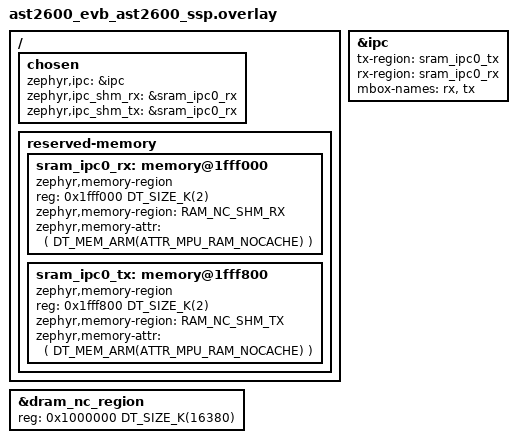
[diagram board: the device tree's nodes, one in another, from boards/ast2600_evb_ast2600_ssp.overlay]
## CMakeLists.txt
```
# SPDX-License-Identifier: Apache-2.0

cmake_minimum_required(VERSION 3.20.0)

find_package(Zephyr REQUIRED HINTS $ENV{ZEPHYR_BASE})
project(ipm_aspeed)

target_include_directories(app PRIVATE ${ZEPHYR_BASE}/drivers)
target_sources(app PRIVATE src/main.c)
```

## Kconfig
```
# Private config options for shared memory sample app

# Copyright (c) 2020 Linaro Limited
# SPDX-License-Identifier: Apache-2.0

# Workaround for not being able to have commas in macro arguments
DT_CHOSEN_Z_IPC := zephyr,ipc_legacy
DT_CHOSEN_Z_IPC_RX_SHM := zephyr,ipc_shm_rx
DT_CHOSEN_Z_IPC_TX_SHM := zephyr,ipc_shm_tx

config OPENAMP_IPC_DEV_NAME
	string
	default "$(dt_chosen_label,$(DT_CHOSEN_Z_IPC))"
	help
	  This option specifies the device name for the IPC device to be used

config IPC_SHM_RX_SIZE
	hex
	default "$(dt_chosen_reg_size_hex,$(DT_CHOSEN_Z_IPC_RX_SHM))"
	help
	  This option specifies size of the memory region to be used
	  for the IPC shared memory

config IPC_SHM_TX_SIZE
	hex
	default "$(dt_chosen_reg_size_hex,$(DT_CHOSEN_Z_IPC_TX_SHM))"
	help
	  This option specifies size of the memory region to be used
	  for the IPC shared memory

source "Kconfig.zephyr"
```

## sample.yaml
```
sample:
  description: the sample reads the received data from the Messaging Unit
    using the IPM and transmits it back unchanged
  name: Aspeed IPM sample
tests:
  sample.ipm.ipm_aspeed:
    build_only: true
    filter: CONFIG_SOC_FAMILY_ASPEED
    platform_allow:
      - ast2700_evb/ast2700/ssp
      - ast2700_evb/ast2700/tsp
      - ast2600_evb/ast2600/ssp
    integration_platforms:
      - ast2700_evb/ast2700/ssp
      - ast2700_evb/ast2700/tsp
      - ast2600_evb/ast2600/ssp
    tags: samples ipm
```

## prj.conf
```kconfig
CONFIG_STDOUT_CONSOLE=n
CONFIG_LOG=y
CONFIG_PRINTK=y
CONFIG_IPM=y
CONFIG_SHELL=y
```

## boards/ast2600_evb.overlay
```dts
/ {
	chosen {
		zephyr,ipc = &ipc;
	};
};

&ipc {
	status = "okay";
	shm_size = <DT_SIZE_K(4)>;
};
```

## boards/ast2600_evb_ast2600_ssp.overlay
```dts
/* SPDX-License-Identifier: Apache-2.0 */

#include <zephyr/dt-bindings/memory-attr/memory-attr-arm.h>

/ {
	chosen {
		zephyr,ipc = &ipc;
		zephyr,ipc_shm_rx = &sram_ipc0_rx;
		zephyr,ipc_shm_tx = &sram_ipc0_rx;
	};

	reserved-memory {
		#address-cells = <1>;
		#size-cells = <1>;
		ranges;
		/* SRAM allocated to shared memory */
		sram_ipc0_rx: memory@1fff000 {
			compatible = "zephyr,memory-region", "mmio-dram";
			reg = <0x1fff000 DT_SIZE_K(2)>;
			zephyr,memory-region = "RAM_NC_SHM_RX";
			zephyr,memory-attr = <( DT_MEM_ARM(ATTR_MPU_RAM_NOCACHE) )>;
		};

		/* SRAM allocated to shared memory */
		sram_ipc0_tx: memory@1fff800 {
			compatible = "zephyr,memory-region", "mmio-dram";
			device_type = "memory";
			reg = <0x1fff800 DT_SIZE_K(2)>;
			zephyr,memory-region = "RAM_NC_SHM_TX";
			zephyr,memory-attr = <( DT_MEM_ARM(ATTR_MPU_RAM_NOCACHE) )>;
		};
	};
};

&dram_nc_region {
	reg = <0x1000000 DT_SIZE_K(16380)>;
};

&ipc {
	tx-region = <&sram_ipc0_tx>;
	rx-region = <&sram_ipc0_rx>;
	mbox-names = "rx", "tx";
	status = "okay";
};
```

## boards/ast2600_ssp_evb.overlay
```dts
/ {
	chosen {
		zephyr,ipc = &ipc;
		zephyr,ipc_shm_rx = &sram_ipc0_rx;
		zephyr,ipc_shm_tx = &sram_ipc0_rx;
	};

	reserved-memory {
		#address-cells = <1>;
		#size-cells = <1>;
		ranges;
		/* SRAM allocated to shared memory */
		sram_ipc0_rx: memory@1fff000 {
			compatible = "zephyr,memory-region", "mmio-dram";
			reg = <0x1fff000 DT_SIZE_K(2)>;
			zephyr,memory-region = "RAM_NC_SHM_RX";
			zephyr,memory-region-mpu = "RAM";
		};

		/* SRAM allocated to shared memory */
		sram_ipc0_tx: memory@1fff800 {
			compatible = "zephyr,memory-region", "mmio-dram";
			device_type = "memory";
			reg = <0x1fff800 DT_SIZE_K(2)>;
			zephyr,memory-region = "RAM_NC_SHM_TX";
			zephyr,memory-region-mpu = "RAM";
		};
	};
};

&sdram1 {
	reg = <0x1000000 DT_SIZE_K(16380)>;
};

&ipc {
	tx-region = <&sram_ipc0_tx>;
	rx-region = <&sram_ipc0_rx>;
	mbox-names = "rx", "tx";
	status = "okay";
};
```

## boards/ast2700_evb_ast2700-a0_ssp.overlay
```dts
/* SPDX-License-Identifier: Apache-2.0 */

#include <zephyr/dt-bindings/memory-attr/memory-attr-arm.h>

/ {
	chosen {
		zephyr,ipc = &ipc_legacy;
		zephyr,ipc_shm_rx = &sram_ipc0_rx;
		zephyr,ipc_shm_tx = &sram_ipc0_tx;
	};

	reserved-memory {
		#address-cells = <1>;
		#size-cells = <1>;
		ranges;
		/* SRAM allocated to shared memory */
		sram_ipc0_rx: memory@ff000 {
			compatible = "zephyr,memory-region", "mmio-dram";
			reg = <0xff000 DT_SIZE_K(2)>;
			zephyr,memory-region = "RAM_NC_SHM_RX";
			zephyr,memory-attr = <( DT_MEM_ARM(ATTR_MPU_RAM_NOCACHE) )>;
		};

		/* SRAM allocated to shared memory */
		sram_ipc0_tx: memory@ff800 {
			compatible = "zephyr,memory-region", "mmio-dram";
			device_type = "memory";
			reg = <0xff800 DT_SIZE_K(2)>;
			zephyr,memory-region = "RAM_NC_SHM_TX";
			zephyr,memory-attr = <( DT_MEM_ARM(ATTR_MPU_RAM_NOCACHE) )>;
		};
	};
};

&dram_nc_region {
	reg = <0xc0000 DT_SIZE_K(252)>;
};

&ipc_legacy {
	tx-region = <&sram_ipc0_tx>;
	rx-region = <&sram_ipc0_rx>;
	mbox-names = "rx", "tx";
	status = "okay";
};
```

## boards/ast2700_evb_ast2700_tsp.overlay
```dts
/* SPDX-License-Identifier: Apache-2.0 */

#include <zephyr/dt-bindings/memory-attr/memory-attr-arm.h>

/ {
	chosen {
		zephyr,ipc = &ipc;
		zephyr,ipc_shm_rx = &sram_ipc0_rx;
		zephyr,ipc_shm_tx = &sram_ipc0_tx;
	};

	reserved-memory {
		#address-cells = <1>;
		#size-cells = <1>;
		ranges;
		/* SRAM allocated to shared memory */
		sram_ipc0_rx: memory@ff000 {
			compatible = "zephyr,memory-region", "mmio-dram";
			reg = <0xff000 DT_SIZE_K(2)>;
			zephyr,memory-region = "RAM_NC_SHM_RX";
			zephyr,memory-attr = <( DT_MEM_ARM(ATTR_MPU_RAM_NOCACHE) )>;
		};

		/* SRAM allocated to shared memory */
		sram_ipc0_tx: memory@ff800 {
			compatible = "zephyr,memory-region", "mmio-dram";
			device_type = "memory";
			reg = <0xff800 DT_SIZE_K(2)>;
			zephyr,memory-region = "RAM_NC_SHM_TX";
			zephyr,memory-attr = <( DT_MEM_ARM(ATTR_MPU_RAM_NOCACHE) )>;
		};
	};
};

&dram_nc_region {
	reg = <0xc0000 DT_SIZE_K(252)>;
};

&ipc {
	tx-region = <&sram_ipc0_tx>;
	rx-region = <&sram_ipc0_rx>;
	mbox-names = "rx", "tx";
	status = "okay";
};
```

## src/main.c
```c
#include <zephyr/kernel.h>
#include <zephyr/logging/log.h>
#include <zephyr/drivers/ipm.h>
#include <string.h>

#if defined(CONFIG_IPM_AST2600)
extern uint8_t *shm_rx, *shm_tx;
#elif defined(CONFIG_IPM_AST2700)
#define DEFAULT_LINE_LENGTH_BYTES (16)
#endif
static void test_ipm_cb(const struct device *ipmdev, void *user_data,
			       uint32_t id, volatile void *data)
{
#if defined(CONFIG_IPM_AST2600)
	int i;
	uint32_t shared_memory_rx = (uint32_t)&shm_rx;
	uint32_t shared_memory_tx = (uint32_t)&shm_tx;

	printk("[SSP] rx addr:%08x, tx addr:%08x\n", shared_memory_rx, shared_memory_tx);
	/* Check the SSP RX data from PSP RX data. */
	printk("PSP RX data from PSP TX data:\n");
	for (i = 0; i < CONFIG_IPC_SHM_RX_SIZE; i += 4) {
		if (sys_read32(shared_memory_rx + i) != 0) {
			if (((i >> 2) & 0x3) == 0x0)
				printk("[%08x] ", shared_memory_rx + i);
			printk("%08x ", sys_read32(shared_memory_rx + i));
			if (((i >> 2) & 0x3) == 0x3)
				printk("\n");
		} else
			break;
	}

	/* Write back to SSP TX from SSP RX data. */
	ipm_send(ipmdev, 1, 0, (void *)shared_memory_rx, CONFIG_IPC_SHM_TX_SIZE);
#elif defined(CONFIG_IPM_AST2700)
	int i;
	int check = 0;
	int width = 4;
	int linelen = DEFAULT_LINE_LENGTH_BYTES/width;
	int max_data_size = ipm_max_data_size_get(ipmdev);
	uint32_t *buf = (uint32_t *)data;

	printk("%s:msg id %x, msg data at %p\n", __func__, id, data);

	for (i = 0; i < max_data_size/sizeof(buf) ; i++) {
		/* FAIL when buf is not golden value */
		if (buf[i] != 0x1688a8a8)
			check = 1;
	}

	/* Check golden fail to print the msg data */
	if (check)
		while (max_data_size) {
			printk("%p:", buf);

			for (i = 0; i < linelen; i++)
				printk(" %08x ", buf[i]);
			printk("\n");
			buf += linelen;
			max_data_size -= linelen * width;
		}
	else
		printk("Check msg data: pass.\n");
#endif
}

int main(void)
{
	int rc = 0;
	const struct device *ipmdev;

#if defined(CONFIG_IPM_AST2600)
	/* setup IPM */
	ipmdev = device_get_binding(CONFIG_OPENAMP_IPC_DEV_NAME);
	if (!ipmdev) {
		printk("device_get_binding failed to find device\n");
		rc = 1;
		goto fail;
	}

	/* setup callback function with received data processing. */
	ipm_register_callback(ipmdev, test_ipm_cb, NULL);

	/* enable ipm. */
	rc = ipm_set_enabled(ipmdev, 1);
	if (rc) {
		printk("cannot ipm_set_enabled\n");
		goto fail;
	}
#elif defined(CONFIG_IPM_AST2700)
	char ipc_name[16];
	int device_id, enable;
#if defined(CONFIG_BOARD_AST2700_EVB_AST2700_SSP) ||                                               \
	defined(CONFIG_BOARD_AST2700_EVB_AST2700_A1_SSP)
	printk("SSP alive.\n");
	strcpy(ipc_name, "ipc0@0");
	ipmdev = device_get_binding(&ipc_name[0]);
	if (!ipmdev) {
		printk("%s: device_get_binding failed to find device\n", ipc_name);
		rc = 1;
		goto fail;
	}

	device_id = 0;
	enable = 1;
	ipm_register_id_callback(ipmdev, device_id, test_ipm_cb, NULL);
	rc = ipm_set_id_enabled(ipmdev, device_id, enable);
	if (rc) {
		printk("%s: cannot ipm_set_enabled\n", ipc_name);
		goto fail;
	}

	strcpy(ipc_name, "ipc0@200");
	ipmdev = device_get_binding(&ipc_name[0]);
	if (!ipmdev) {
		printk("%s: device_get_binding failed to find device\n", ipc_name);
		rc = 1;
		goto fail;
	}

	device_id = 0;
	enable = 1;
	ipm_register_id_callback(ipmdev, device_id, test_ipm_cb, NULL);
	rc = ipm_set_id_enabled(ipmdev, device_id, enable);
	if (rc) {
		printk("%s: cannot ipm_set_enabled\n", ipc_name);
		goto fail;
	}
#endif /* defined(CONFIG_BOARD_AST2700_EVB_AST2700_SSP) */
#if defined(CONFIG_BOARD_AST2700_EVB_AST2700_TSP) ||                                               \
	defined(CONFIG_BOARD_AST2700_EVB_AST2700_A1_TSP)
	printk("TSP alive.\n");
	strcpy(ipc_name, "ipc0@400");
	ipmdev = device_get_binding(&ipc_name[0]);
	if (!ipmdev) {
		printk("%s: device_get_binding failed to find device\n", ipc_name);
		rc = 1;
		goto fail;
	}

	device_id = 0;
	enable = 1;
	ipm_register_id_callback(ipmdev, device_id, test_ipm_cb, NULL);
	rc = ipm_set_id_enabled(ipmdev, device_id, enable);
	if (rc) {
		printk("%s: cannot ipm_set_enabled\n", ipc_name);
		goto fail;
	}

	strcpy(ipc_name, "ipc0@600");
	ipmdev = device_get_binding(&ipc_name[0]);
	if (!ipmdev) {
		printk("%s: device_get_binding failed to find device\n", ipc_name);
		rc = 1;
		goto fail;
	}

	device_id = 0;
	enable = 1;
	ipm_register_id_callback(ipmdev, device_id, test_ipm_cb, NULL);
	rc = ipm_set_id_enabled(ipmdev, device_id, enable);
	if (rc) {
		printk("%s: cannot ipm_set_enabled\n", ipc_name);
		goto fail;
	}
#endif /* defined(CONFIG_BOARD_AST2700_EVB_AST2700_TSP) */

	strcpy(ipc_name, "ipc0@800");
	ipmdev = device_get_binding(&ipc_name[0]);
	if (!ipmdev) {
		printk("%s: device_get_binding failed to find device\n", ipc_name);
		rc = 1;
		goto fail;
	}

	device_id = 0;
	enable = 1;
	ipm_register_id_callback(ipmdev, device_id, test_ipm_cb, NULL);
	rc = ipm_set_id_enabled(ipmdev, device_id, enable);
	if (rc) {
		printk("%s: cannot ipm_set_enabled\n", ipc_name);
		goto fail;
	}
#endif /* defined(CONFIG_IPM_AST2700) */
	printk("All IPMs initialized\n");

	while (1) {
		k_msleep(1000);
	}

fail:
	return rc;
}
```
